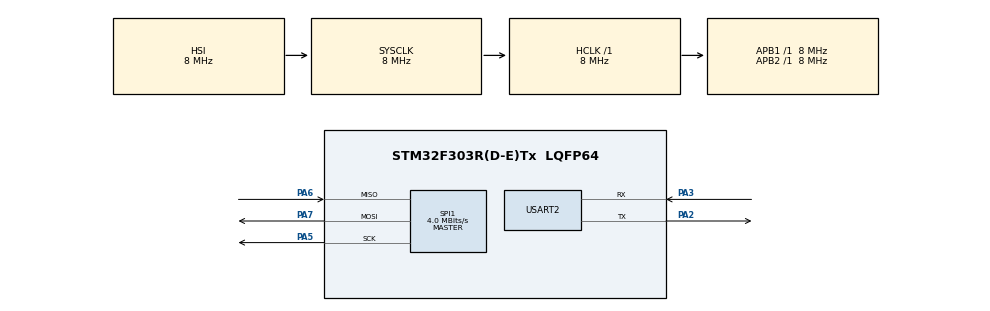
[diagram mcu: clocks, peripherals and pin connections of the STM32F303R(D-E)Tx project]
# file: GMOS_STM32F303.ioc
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Mcu.Family=STM32F3
Mcu.Name=STM32F303R(D-E)Tx
Mcu.Package=LQFP64
NVIC.PriorityGroup=NVIC_PRIORITYGROUP_4
NVIC.USART2_IRQn=true\:0\:0\:false\:false\:true\:true\:true\:true
PA13.Mode=Serial_Wire
PA13.Signal=SYS_JTMS-SWDIO
PA14.Mode=Serial_Wire
PA14.Signal=SYS_JTCK-SWCLK
PA2.Mode=Asynchronous
PA2.Signal=USART2_TX
PA3.Mode=Asynchronous
PA3.Signal=USART2_RX
PA5.Mode=Full_Duplex_Master
PA5.Signal=SPI1_SCK
PA6.Mode=Full_Duplex_Master
PA6.Signal=SPI1_MISO
PA7.Mode=Full_Duplex_Master
PA7.Signal=SPI1_MOSI
PC14-OSC32_IN.Mode=LSE-External-Oscillator
PC14-OSC32_IN.Signal=RCC_OSC32_IN
PC15-OSC32_OUT.Mode=LSE-External-Oscillator
PC15-OSC32_OUT.Signal=RCC_OSC32_OUT
PF0-OSC_IN.Mode=HSE-External-Clock-Source
PF0-OSC_IN.Signal=RCC_OSC_IN
ProjectManager.HeapSize=0x200
ProjectManager.StackSize=0x400
ProjectManager.TargetToolchain=STM32CubeIDE
RCC.AHBFreq_Value=8000000
RCC.APB1Freq_Value=8000000
RCC.APB2Freq_Value=8000000
RCC.CortexFreq_Value=8000000
RCC.HSE_VALUE=8000000
RCC.HSI_VALUE=8000000
RCC.SYSCLKFreq_VALUE=8000000
RCC.USBFreq_Value=16000000
SPI1.CalculateBaudRate=4.0 MBits/s
SPI1.Direction=SPI_DIRECTION_2LINES
SPI1.Mode=SPI_MODE_MASTER
SPI1.VirtualType=VM_MASTER
USART2.VirtualMode-Asynchronous=VM_ASYNC
VP_RTC_VS_RTC_Activate.Mode=RTC_Enabled
board=custom

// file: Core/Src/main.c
/* USER CODE BEGIN Header */
/**
  ******************************************************************************
  * @file           : main.c
  * @brief          : Main program body
  ******************************************************************************
  * @attention
  *
  * Copyright (c) 2024 STMicroelectronics.
  * All rights reserved.
  *
  * This software is licensed under terms that can be found in the LICENSE file
  * in the root directory of this software component.
  * If no LICENSE file comes with this software, it is provided AS-IS.
  *
  ******************************************************************************
  */
/* USER CODE END Header */
#include "main.h"

RTC_HandleTypeDef hrtc;

SPI_HandleTypeDef hspi1;

UART_HandleTypeDef huart2;

void SystemClock_Config(void);
static void MX_GPIO_Init(void);
static void MX_RTC_Init(void);
static void MX_SPI1_Init(void);
static void MX_USART2_UART_Init(void);

int main(void)
{

  /* MCU Configuration--------------------------------------------------------*/

  /* Reset of all peripherals, Initializes the Flash interface and the Systick. */
  HAL_Init();

  /* Configure the system clock */
  SystemClock_Config();

  /* Initialize all configured peripherals */
  MX_GPIO_Init();
  MX_RTC_Init();
  MX_SPI1_Init();
  MX_USART2_UART_Init();
  /* USER CODE BEGIN 2 */
  BSP_Init();
  /* USER CODE END 2 */

  /* Infinite loop */
  while (1)
  {

    /* USER CODE BEGIN 3 */
	  Consume_Message();
	  HAL_Delay(100);
	  HAL_SuspendTick();
	  HAL_PWR_EnterSLEEPMode(PWR_MAINREGULATOR_ON, PWR_SLEEPENTRY_WFI);
	  HAL_ResumeTick();
  }
  /* USER CODE END 3 */
}

void SystemClock_Config(void)
{
  RCC_OscInitTypeDef RCC_OscInitStruct = {0};
  RCC_ClkInitTypeDef RCC_ClkInitStruct = {0};
  RCC_PeriphCLKInitTypeDef PeriphClkInit = {0};

  /** Initializes the RCC Oscillators according to the specified parameters
  * in the RCC_OscInitTypeDef structure.
  */
  RCC_OscInitStruct.OscillatorType = RCC_OSCILLATORTYPE_HSI|RCC_OSCILLATORTYPE_LSI;
  RCC_OscInitStruct.HSIState = RCC_HSI_ON;
  RCC_OscInitStruct.HSICalibrationValue = RCC_HSICALIBRATION_DEFAULT;
  RCC_OscInitStruct.LSIState = RCC_LSI_ON;
  RCC_OscInitStruct.PLL.PLLState = RCC_PLL_NONE;
  if (HAL_RCC_OscConfig(&RCC_OscInitStruct) != HAL_OK)
  {
    Error_Handler();
  }

  /** Initializes the CPU, AHB and APB buses clocks
  */
  RCC_ClkInitStruct.ClockType = RCC_CLOCKTYPE_HCLK|RCC_CLOCKTYPE_SYSCLK
                              |RCC_CLOCKTYPE_PCLK1|RCC_CLOCKTYPE_PCLK2;
  RCC_ClkInitStruct.SYSCLKSource = RCC_SYSCLKSOURCE_HSI;
  RCC_ClkInitStruct.AHBCLKDivider = RCC_SYSCLK_DIV1;
  RCC_ClkInitStruct.APB1CLKDivider = RCC_HCLK_DIV1;
  RCC_ClkInitStruct.APB2CLKDivider = RCC_HCLK_DIV1;

  if (HAL_RCC_ClockConfig(&RCC_ClkInitStruct, FLASH_LATENCY_0) != HAL_OK)
  {
    Error_Handler();
  }
  PeriphClkInit.PeriphClockSelection = RCC_PERIPHCLK_USART2|RCC_PERIPHCLK_RTC;
  PeriphClkInit.Usart2ClockSelection = RCC_USART2CLKSOURCE_PCLK1;
  PeriphClkInit.RTCClockSelection = RCC_RTCCLKSOURCE_LSI;
  if (HAL_RCCEx_PeriphCLKConfig(&PeriphClkInit) != HAL_OK)
  {
    Error_Handler();
  }
}

static void MX_RTC_Init(void)
{

  /** Initialize RTC Only
  */
  hrtc.Instance = RTC;
  hrtc.Init.HourFormat = RTC_HOURFORMAT_24;
  hrtc.Init.AsynchPrediv = 127;
  hrtc.Init.SynchPrediv = 255;
  hrtc.Init.OutPut = RTC_OUTPUT_DISABLE;
  hrtc.Init.OutPutPolarity = RTC_OUTPUT_POLARITY_HIGH;
  hrtc.Init.OutPutType = RTC_OUTPUT_TYPE_OPENDRAIN;
  if (HAL_RTC_Init(&hrtc) != HAL_OK)
  {
    Error_Handler();
  }

}

static void MX_SPI1_Init(void)
{

  /* SPI1 parameter configuration*/
  hspi1.Instance = SPI1;
  hspi1.Init.Mode = SPI_MODE_MASTER;
  hspi1.Init.Direction = SPI_DIRECTION_2LINES;
  hspi1.Init.DataSize = SPI_DATASIZE_4BIT;
  hspi1.Init.CLKPolarity = SPI_POLARITY_LOW;
  hspi1.Init.CLKPhase = SPI_PHASE_1EDGE;
  hspi1.Init.NSS = SPI_NSS_SOFT;
  hspi1.Init.BaudRatePrescaler = SPI_BAUDRATEPRESCALER_2;
  hspi1.Init.FirstBit = SPI_FIRSTBIT_MSB;
  hspi1.Init.TIMode = SPI_TIMODE_DISABLE;
  hspi1.Init.CRCCalculation = SPI_CRCCALCULATION_DISABLE;
  hspi1.Init.CRCPolynomial = 7;
  hspi1.Init.CRCLength = SPI_CRC_LENGTH_DATASIZE;
  hspi1.Init.NSSPMode = SPI_NSS_PULSE_ENABLE;
  if (HAL_SPI_Init(&hspi1) != HAL_OK)
  {
    Error_Handler();
  }

}

static void MX_USART2_UART_Init(void)
{

  huart2.Instance = USART2;
  huart2.Init.BaudRate = 38400;
  huart2.Init.WordLength = UART_WORDLENGTH_8B;
  huart2.Init.StopBits = UART_STOPBITS_1;
  huart2.Init.Parity = UART_PARITY_NONE;
  huart2.Init.Mode = UART_MODE_TX_RX;
  huart2.Init.HwFlowCtl = UART_HWCONTROL_NONE;
  huart2.Init.OverSampling = UART_OVERSAMPLING_16;
  huart2.Init.OneBitSampling = UART_ONE_BIT_SAMPLE_DISABLE;
  huart2.AdvancedInit.AdvFeatureInit = UART_ADVFEATURE_NO_INIT;
  if (HAL_UART_Init(&huart2) != HAL_OK)
  {
    Error_Handler();
  }

}

static void MX_GPIO_Init(void)
{

  /* GPIO Ports Clock Enable */
  __HAL_RCC_GPIOC_CLK_ENABLE();
  __HAL_RCC_GPIOF_CLK_ENABLE();
  __HAL_RCC_GPIOA_CLK_ENABLE();

}

void Error_Handler(void)
{
  __disable_irq();
  while (1)
  {
  }
}
